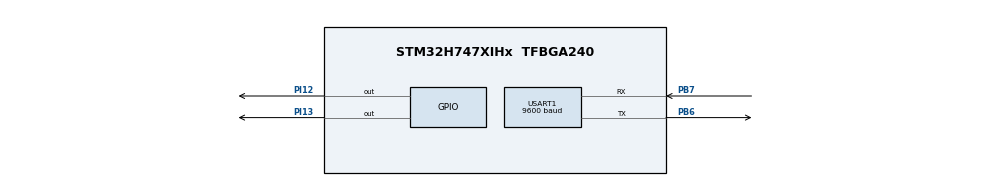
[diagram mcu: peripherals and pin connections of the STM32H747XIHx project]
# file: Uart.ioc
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Mcu.Family=STM32H7
PB7.PinAttribute=CortexM7
RCC.CortexFreq_Value=64000000
USART1.BaudRate=9600
CortexM4.Pins=PI12
NVIC1.PriorityGroup=NVIC_PRIORITYGROUP_4
PI12.Signal=GPIO_Output
RCC.PLL2FRACN=3072
RCC.PWR_Regulator_Voltage_Scale=PWR_REGULATOR_VOLTAGE_SCALE1
ProjectManager.StackSize=0x400
PB6.PinAttribute=CortexM7
USART1.VirtualMode-Asynchronous=VM_ASYNC
ProjectManager.TargetToolchain=STM32CubeIDE
PI13.PinAttribute=CortexM7
RCC.HCLKFreq_Value=64000000
PB6.Signal=USART1_TX
RCC.DIVN2=9
PB6.Mode=Asynchronous
RCC.USBFreq_Value=129000000
PI13.Signal=GPIO_Output
board=STM32H747I-DISCO
RCC.DIVM2=4
RCC.APB2Freq_Value=64000000
NVIC2.PriorityGroup=NVIC_PRIORITYGROUP_4
PI12.PinAttribute=CortexM4
RCC.ADCFreq_Value=75000000
VP_SYS_M4_VS_Systick.Mode=SysTick
PB7.Signal=USART1_RX
CortexM7.Pins=PI13
CortexM7.IPs=BDMA\:I,DMA\:I,FATFS_M7\:I,FREERTOS_M7\:I,IWDG1\:I,MDMA\:I,NVIC1\:I,RCC\:I,USB_DEVICE_M7\:I,USB_HOST_M7\:I,WWDG1\:I,CORTEX_M7\:I,DEBUG\:I,PDM2PCM_M7\:I,PWR\:I,RESMGR_UTILITY\:I,SYS\:I,OPENAMP_M7\:I,VREFBUF\:I,USART1\:I
Mcu.Name=STM32H747XIHx
RCC.APB3Freq_Value=64000000
RCC.SYSCLKFreq_VALUE=64000000
Mcu.Package=TFBGA240
PB7.Mode=Asynchronous
ProjectManager.HeapSize=0x200
RCC.APB4Freq_Value=64000000
RCC.APB1Freq_Value=64000000
RCC.SupplySource=PWR_DIRECT_SMPS_SUPPLY
CortexM4.IPs=BDMA,DMA,FATFS_M4\:I,FREERTOS_M4\:I,IWDG2\:I,MDMA,NVIC2\:I,RCC,USB_DEVICE_M4\:I,USB_HOST_M4\:I,WWDG2\:I,DCMI\:I,TIM3\:I,DEBUG,PDM2PCM_M4\:I,PWR,RESMGR_UTILITY,SYS_M4\:I,CORTEX_M4\:I,OPENAMP_M4\:I,VREFBUF

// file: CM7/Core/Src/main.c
/* USER CODE BEGIN Header */
/**
  ******************************************************************************
  * @file           : main.c
  * @brief          : Main program body
  ******************************************************************************
  * @attention
  *
  * <h2><center>&copy; Copyright (c) 2021 STMicroelectronics.
  * All rights reserved.</center></h2>
  *
  * This software component is licensed by ST under BSD 3-Clause license,
  * the "License"; You may not use this file except in compliance with the
  * License. You may obtain a copy of the License at:
  *                        opensource.org/licenses/BSD-3-Clause
  *
  ******************************************************************************
  */
/* USER CODE END Header */
#include "main.h"

/* USER CODE BEGIN PD */

#ifndef HSEM_ID_0
#define HSEM_ID_0 (0U) /* HW semaphore 0*/
#endif
/* USER CODE END PD */

UART_HandleTypeDef huart1;

void SystemClock_Config(void);
static void MX_GPIO_Init(void);
static void MX_USART1_UART_Init(void);

int main(void)
{
  /* USER CODE BEGIN 1 */
	uint8_t word [7]="teste\n\r";

  /* USER CODE END 1 */
/* USER CODE BEGIN Boot_Mode_Sequence_0 */
  int32_t timeout;
/* USER CODE END Boot_Mode_Sequence_0 */

/* USER CODE BEGIN Boot_Mode_Sequence_1 */
  /* Wait until CPU2 boots and enters in stop mode or timeout*/
  timeout = 0xFFFF;
  while((__HAL_RCC_GET_FLAG(RCC_FLAG_D2CKRDY) != RESET) && (timeout-- > 0));
  if ( timeout < 0 )
  {
  Error_Handler();
  }
/* USER CODE END Boot_Mode_Sequence_1 */
  /* MCU Configuration--------------------------------------------------------*/

  /* Reset of all peripherals, Initializes the Flash interface and the Systick. */
  HAL_Init();

  /* Configure the system clock */
  SystemClock_Config();
/* USER CODE BEGIN Boot_Mode_Sequence_2 */
/* When system initialization is finished, Cortex-M7 will release Cortex-M4 by means of
HSEM notification */
/*HW semaphore Clock enable*/
__HAL_RCC_HSEM_CLK_ENABLE();
/*Take HSEM */
HAL_HSEM_FastTake(HSEM_ID_0);
/*Release HSEM in order to notify the CPU2(CM4)*/
HAL_HSEM_Release(HSEM_ID_0,0);
/* wait until CPU2 wakes up from stop mode */
timeout = 0xFFFF;
while((__HAL_RCC_GET_FLAG(RCC_FLAG_D2CKRDY) == RESET) && (timeout-- > 0));
if ( timeout < 0 )
{
Error_Handler();
}
/* USER CODE END Boot_Mode_Sequence_2 */

  /* Initialize all configured peripherals */
  MX_GPIO_Init();
  MX_USART1_UART_Init();

  /* Infinite loop */
  while (1)
  {

    /* USER CODE BEGIN 3 */
	  HAL_UART_Transmit(&huart1, word, 7,100);
	  HAL_GPIO_TogglePin(GPIOI, GPIO_PIN_13);
	  HAL_Delay(500);
  }
  /* USER CODE END 3 */
}

void SystemClock_Config(void)
{
  RCC_OscInitTypeDef RCC_OscInitStruct = {0};
  RCC_ClkInitTypeDef RCC_ClkInitStruct = {0};

  /** Supply configuration update enable
  */
  HAL_PWREx_ConfigSupply(PWR_DIRECT_SMPS_SUPPLY);
  /** Configure the main internal regulator output voltage
  */
  __HAL_PWR_VOLTAGESCALING_CONFIG(PWR_REGULATOR_VOLTAGE_SCALE1);

  while(!__HAL_PWR_GET_FLAG(PWR_FLAG_VOSRDY)) {}
  /** Initializes the RCC Oscillators according to the specified parameters
  * in the RCC_OscInitTypeDef structure.
  */
  RCC_OscInitStruct.OscillatorType = RCC_OSCILLATORTYPE_HSI;
  RCC_OscInitStruct.HSIState = RCC_HSI_DIV1;
  RCC_OscInitStruct.HSICalibrationValue = RCC_HSICALIBRATION_DEFAULT;
  RCC_OscInitStruct.PLL.PLLState = RCC_PLL_NONE;
  if (HAL_RCC_OscConfig(&RCC_OscInitStruct) != HAL_OK)
  {
    Error_Handler();
  }
  /** Initializes the CPU, AHB and APB buses clocks
  */
  RCC_ClkInitStruct.ClockType = RCC_CLOCKTYPE_HCLK|RCC_CLOCKTYPE_SYSCLK
                              |RCC_CLOCKTYPE_PCLK1|RCC_CLOCKTYPE_PCLK2
                              |RCC_CLOCKTYPE_D3PCLK1|RCC_CLOCKTYPE_D1PCLK1;
  RCC_ClkInitStruct.SYSCLKSource = RCC_SYSCLKSOURCE_HSI;
  RCC_ClkInitStruct.SYSCLKDivider = RCC_SYSCLK_DIV1;
  RCC_ClkInitStruct.AHBCLKDivider = RCC_HCLK_DIV1;
  RCC_ClkInitStruct.APB3CLKDivider = RCC_APB3_DIV1;
  RCC_ClkInitStruct.APB1CLKDivider = RCC_APB1_DIV1;
  RCC_ClkInitStruct.APB2CLKDivider = RCC_APB2_DIV1;
  RCC_ClkInitStruct.APB4CLKDivider = RCC_APB4_DIV1;

  if (HAL_RCC_ClockConfig(&RCC_ClkInitStruct, FLASH_LATENCY_0) != HAL_OK)
  {
    Error_Handler();
  }
}

static void MX_USART1_UART_Init(void)
{

  huart1.Instance = USART1;
  huart1.Init.BaudRate = 9600;
  huart1.Init.WordLength = UART_WORDLENGTH_8B;
  huart1.Init.StopBits = UART_STOPBITS_1;
  huart1.Init.Parity = UART_PARITY_NONE;
  huart1.Init.Mode = UART_MODE_TX_RX;
  huart1.Init.HwFlowCtl = UART_HWCONTROL_NONE;
  huart1.Init.OverSampling = UART_OVERSAMPLING_16;
  huart1.Init.OneBitSampling = UART_ONE_BIT_SAMPLE_DISABLE;
  huart1.Init.ClockPrescaler = UART_PRESCALER_DIV1;
  huart1.AdvancedInit.AdvFeatureInit = UART_ADVFEATURE_NO_INIT;
  if (HAL_UART_Init(&huart1) != HAL_OK)
  {
    Error_Handler();
  }
  if (HAL_UARTEx_SetTxFifoThreshold(&huart1, UART_TXFIFO_THRESHOLD_1_8) != HAL_OK)
  {
    Error_Handler();
  }
  if (HAL_UARTEx_SetRxFifoThreshold(&huart1, UART_RXFIFO_THRESHOLD_1_8) != HAL_OK)
  {
    Error_Handler();
  }
  if (HAL_UARTEx_DisableFifoMode(&huart1) != HAL_OK)
  {
    Error_Handler();
  }

}

static void MX_GPIO_Init(void)
{
  GPIO_InitTypeDef GPIO_InitStruct = {0};

  /* GPIO Ports Clock Enable */
  __HAL_RCC_GPIOB_CLK_ENABLE();
  __HAL_RCC_GPIOI_CLK_ENABLE();

  /*Configure GPIO pin Output Level */
  HAL_GPIO_WritePin(GPIOI, GPIO_PIN_13, GPIO_PIN_RESET);

  /*Configure GPIO pin : PI13 */
  GPIO_InitStruct.Pin = GPIO_PIN_13;
  GPIO_InitStruct.Mode = GPIO_MODE_OUTPUT_PP;
  GPIO_InitStruct.Pull = GPIO_NOPULL;
  GPIO_InitStruct.Speed = GPIO_SPEED_FREQ_LOW;
  HAL_GPIO_Init(GPIOI, &GPIO_InitStruct);

}

void Error_Handler(void)
{
  __disable_irq();
  while (1)
  {
  }
}

/************************ (C) COPYRIGHT STMicroelectronics *****END OF FILE****/
